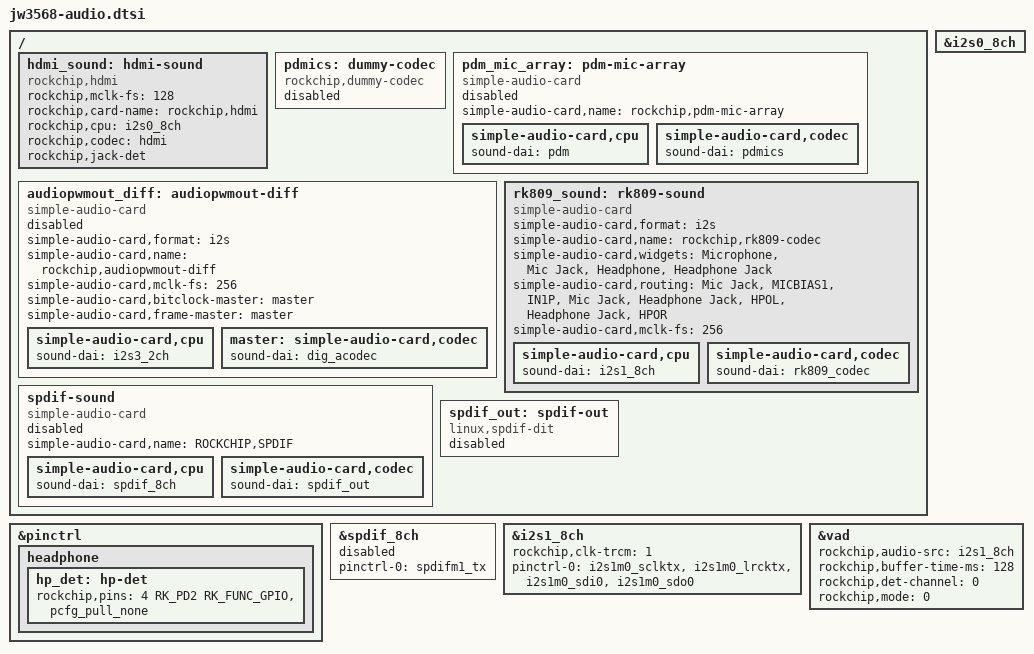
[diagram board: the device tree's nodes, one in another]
/ {
	hdmi_sound: hdmi-sound {
		status = "okay";
		compatible = "rockchip,hdmi";
		rockchip,mclk-fs = <128>;
		rockchip,card-name = "rockchip,hdmi";
		rockchip,cpu = <&i2s0_8ch>;
		rockchip,codec = <&hdmi>;
		rockchip,jack-det;
	};

	pdmics: dummy-codec {
		status = "disabled";
		compatible = "rockchip,dummy-codec";
		#sound-dai-cells = <0>;
	};

	pdm_mic_array: pdm-mic-array {
		status = "disabled";
		compatible = "simple-audio-card";
		simple-audio-card,name = "rockchip,pdm-mic-array";
		simple-audio-card,cpu {
			sound-dai = <&pdm>;
		};
		simple-audio-card,codec {
			sound-dai = <&pdmics>;
		};
	};

	audiopwmout_diff: audiopwmout-diff {
		status = "disabled";
		compatible = "simple-audio-card";
		simple-audio-card,format = "i2s";
		simple-audio-card,name = "rockchip,audiopwmout-diff";
		simple-audio-card,mclk-fs = <256>;
		simple-audio-card,bitclock-master = <&master>;
		simple-audio-card,frame-master = <&master>;
		simple-audio-card,cpu {
			sound-dai = <&i2s3_2ch>;
		};
		master: simple-audio-card,codec {
			sound-dai = <&dig_acodec>;
		};
	};


	rk809_sound: rk809-sound {
		status = "okay";
		compatible = "simple-audio-card";
		simple-audio-card,format = "i2s";
		simple-audio-card,name = "rockchip,rk809-codec";
		//simple-audio-card,hp-det-gpio = <&gpio4 RK_PD2 GPIO_ACTIVE_HIGH>;
		simple-audio-card,widgets =
			"Microphone", "Mic Jack",
			"Headphone", "Headphone Jack";
		simple-audio-card,routing =
                        "Mic Jack", "MICBIAS1",
                        "IN1P", "Mic Jack",
                        "Headphone Jack", "HPOL",
                        "Headphone Jack", "HPOR";
		simple-audio-card,mclk-fs = <256>;

		simple-audio-card,cpu {
			sound-dai = <&i2s1_8ch>;
		};
		simple-audio-card,codec {
			sound-dai = <&rk809_codec>;
		};
	};

	spdif-sound {
		status = "disabled";
		compatible = "simple-audio-card";
		simple-audio-card,name = "ROCKCHIP,SPDIF";
		simple-audio-card,cpu {
				sound-dai = <&spdif_8ch>;
		};
		simple-audio-card,codec {
				sound-dai = <&spdif_out>;
		};
	};

	spdif_out: spdif-out {
			status = "disabled";
			compatible = "linux,spdif-dit";
			#sound-dai-cells = <0>;
	};
};

&pinctrl {
	headphone {
		hp_det: hp-det {
			rockchip,pins = <4 RK_PD2 RK_FUNC_GPIO &pcfg_pull_none>;
		};
	};

};

&spdif_8ch {
	status = "disabled";
	pinctrl-names = "default";
	pinctrl-0 = <&spdifm1_tx>;
};

&i2s0_8ch {
	status = "okay";
};

&i2s1_8ch {
	status = "okay";
	rockchip,clk-trcm = <1>;
	pinctrl-names = "default";
	pinctrl-0 = <&i2s1m0_sclktx
		     &i2s1m0_lrcktx
		     &i2s1m0_sdi0
		     &i2s1m0_sdo0>;
};

&vad {
	rockchip,audio-src = <&i2s1_8ch>;
	rockchip,buffer-time-ms = <128>;
	rockchip,det-channel = <0>;
	rockchip,mode = <0>;
};
